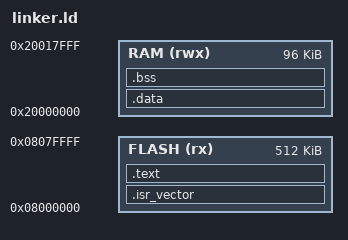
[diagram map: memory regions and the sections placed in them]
/* Minimal STM32F401RE linker script grabbed from ChatGPT*/
/* linker/linker.ld */
MEMORY
{
  FLASH (rx) : ORIGIN = 0x08000000, LENGTH = 512K
  RAM (rwx)  : ORIGIN = 0x20000000, LENGTH = 96K
}

_estack = ORIGIN(RAM) + LENGTH(RAM); /* Stack top */

_sidata = LOADADDR(.data);
_sdata  = .;
_edata  = .;
_sbss   = .;
_ebss   = .;

SECTIONS
{
  .isr_vector :
  {
    KEEP(*(.isr_vector))
  } > FLASH

  .text :
  {
    *(.text*)
    *(.rodata*)
    KEEP(*(.init))
    KEEP(*(.fini))
  } > FLASH

  .data : AT (ADDR(.text) + SIZEOF(.text))
  {
    _sdata = .;
    *(.data*)
    _edata = .;
  } > RAM

  .bss :
  {
    _sbss = .;
    *(.bss*)
    *(COMMON)
    _ebss = .;
  } > RAM
}
